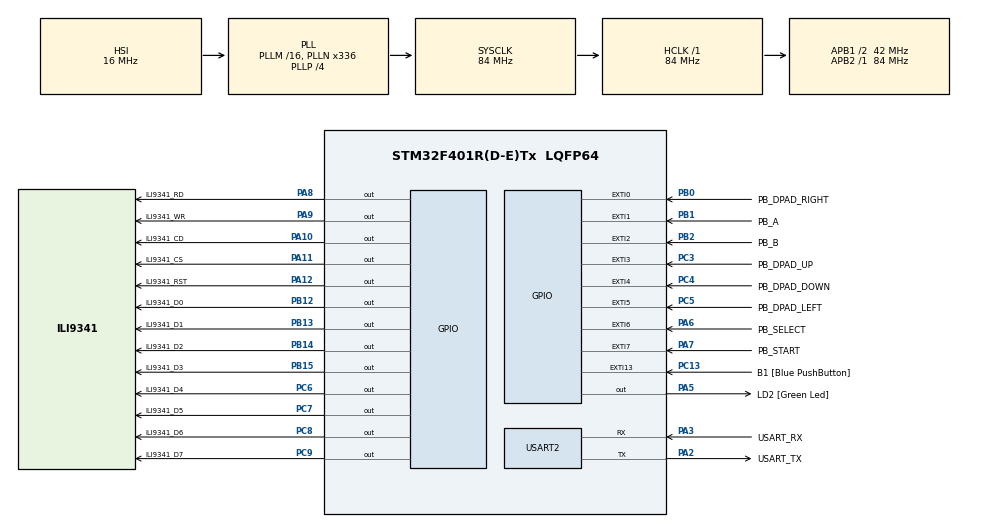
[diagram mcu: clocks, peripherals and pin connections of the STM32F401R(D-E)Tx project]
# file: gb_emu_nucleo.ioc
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Mcu.Family=STM32F4
Mcu.Name=STM32F401R(D-E)Tx
Mcu.Package=LQFP64
NVIC.EXTI0_IRQn=true\:0\:0\:false\:false\:true\:true\:true\:true
NVIC.EXTI1_IRQn=true\:0\:0\:false\:false\:true\:true\:true\:true
NVIC.EXTI2_IRQn=true\:0\:0\:false\:false\:true\:true\:true\:true
NVIC.EXTI3_IRQn=true\:0\:0\:false\:false\:true\:true\:true\:true
NVIC.EXTI4_IRQn=true\:0\:0\:false\:false\:true\:true\:true\:true
NVIC.EXTI9_5_IRQn=true\:0\:0\:false\:false\:true\:true\:true\:true
NVIC.PriorityGroup=NVIC_PRIORITYGROUP_4
PA10.GPIO_Label=ILI9341_CD
PA10.Signal=GPIO_Output
PA11.GPIO_Label=ILI9341_CS
PA11.Signal=GPIO_Output
PA12.GPIO_Label=ILI9341_RST
PA12.Signal=GPIO_Output
PA13.GPIO_Label=TMS
PA13.Mode=Trace_Asynchronous_SW
PA13.Signal=SYS_JTMS-SWDIO
PA14.GPIO_Label=TCK
PA14.Mode=Trace_Asynchronous_SW
PA14.Signal=SYS_JTCK-SWCLK
PA2.GPIO_Label=USART_TX
PA2.GPIO_Mode=GPIO_MODE_AF_PP
PA2.GPIO_PuPd=GPIO_NOPULL
PA2.GPIO_Speed=GPIO_SPEED_FREQ_LOW
PA2.Mode=Asynchronous
PA2.Signal=USART2_TX
PA3.GPIO_Label=USART_RX
PA3.GPIO_Mode=GPIO_MODE_AF_PP
PA3.GPIO_PuPd=GPIO_NOPULL
PA3.GPIO_Speed=GPIO_SPEED_FREQ_LOW
PA3.Mode=Asynchronous
PA3.Signal=USART2_RX
PA5.GPIO_Label=LD2 [Green Led]
PA5.GPIO_Mode=GPIO_MODE_OUTPUT_PP
PA5.GPIO_PuPd=GPIO_NOPULL
PA5.GPIO_Speed=GPIO_SPEED_FREQ_LOW
PA5.Signal=GPIO_Output
PA6.GPIO_Label=PB_SELECT
PA6.GPIO_ModeDefaultEXTI=GPIO_MODE_IT_RISING_FALLING
PA6.Signal=GPXTI6
PA7.GPIO_Label=PB_START
PA7.GPIO_ModeDefaultEXTI=GPIO_MODE_IT_RISING_FALLING
PA7.Signal=GPXTI7
PA8.GPIO_Label=ILI9341_RD
PA8.Signal=GPIO_Output
PA9.GPIO_Label=ILI9341_WR
PA9.Signal=GPIO_Output
PB0.GPIO_Label=PB_DPAD_RIGHT
PB0.GPIO_ModeDefaultEXTI=GPIO_MODE_IT_RISING_FALLING
PB0.Signal=GPXTI0
PB1.GPIO_Label=PB_A
PB1.GPIO_ModeDefaultEXTI=GPIO_MODE_IT_RISING_FALLING
PB1.Signal=GPXTI1
PB12.GPIO_Label=ILI9341_D0
PB12.Signal=GPIO_Output
PB13.GPIO_Label=ILI9341_D1
PB13.Signal=GPIO_Output
PB14.GPIO_Label=ILI9341_D2
PB14.Signal=GPIO_Output
PB15.GPIO_Label=ILI9341_D3
PB15.Signal=GPIO_Output
PB2.GPIO_Label=PB_B
PB2.GPIO_ModeDefaultEXTI=GPIO_MODE_IT_RISING_FALLING
PB2.Signal=GPXTI2
PB3.GPIO_Label=SWO
PB3.Mode=Trace_Asynchronous_SW
PB3.Signal=SYS_JTDO-SWO
PC13-ANTI_TAMP.GPIO_Label=B1 [Blue PushButton]
PC13-ANTI_TAMP.GPIO_ModeDefaultEXTI=GPIO_MODE_IT_FALLING
PC13-ANTI_TAMP.GPIO_PuPd=GPIO_NOPULL
PC13-ANTI_TAMP.Signal=GPXTI13
PC14-OSC32_IN.Mode=LSE-External-Oscillator
PC14-OSC32_IN.Signal=RCC_OSC32_IN
PC15-OSC32_OUT.Mode=LSE-External-Oscillator
PC15-OSC32_OUT.Signal=RCC_OSC32_OUT
PC3.GPIO_Label=PB_DPAD_UP
PC3.GPIO_ModeDefaultEXTI=GPIO_MODE_IT_RISING_FALLING
PC3.Signal=GPXTI3
PC4.GPIO_Label=PB_DPAD_DOWN
PC4.GPIO_ModeDefaultEXTI=GPIO_MODE_IT_RISING_FALLING
PC4.Signal=GPXTI4
PC5.GPIO_Label=PB_DPAD_LEFT
PC5.GPIO_ModeDefaultEXTI=GPIO_MODE_IT_RISING_FALLING
PC5.Signal=GPXTI5
PC6.GPIO_Label=ILI9341_D4
PC6.Signal=GPIO_Output
PC7.GPIO_Label=ILI9341_D5
PC7.Signal=GPIO_Output
PC8.GPIO_Label=ILI9341_D6
PC8.Signal=GPIO_Output
PC9.GPIO_Label=ILI9341_D7
PC9.Signal=GPIO_Output
PH0\ -\ OSC_IN.Mode=HSE-External-Clock-Source
PH0\ -\ OSC_IN.Signal=RCC_OSC_IN
PH1\ -\ OSC_OUT.Mode=HSE-External-Clock-Source
PH1\ -\ OSC_OUT.Signal=RCC_OSC_OUT
ProjectManager.HeapSize=0x200
ProjectManager.StackSize=0x400
ProjectManager.TargetToolchain=STM32CubeIDE
RCC.48MHZClocksFreq_Value=48000000
RCC.AHBFreq_Value=84000000
RCC.APB1CLKDivider=RCC_HCLK_DIV2
RCC.APB1Freq_Value=42000000
RCC.APB1TimFreq_Value=84000000
RCC.APB2Freq_Value=84000000
RCC.APB2TimFreq_Value=84000000
RCC.CortexFreq_Value=84000000
RCC.HCLKFreq_Value=84000000
RCC.HSE_VALUE=8000000
RCC.HSI_VALUE=16000000
RCC.PLLN=336
RCC.PLLP=RCC_PLLP_DIV4
RCC.PLLQ=7
RCC.SYSCLKFreq_VALUE=84000000
RCC.SYSCLKSource=RCC_SYSCLKSOURCE_PLLCLK
RCC.VCOOutputFreq_Value=336000000
TIM10.Channel=TIM_CHANNEL_1
USART2.VirtualMode=VM_ASYNC
VP_TIM10_VS_ClockSourceINT.Mode=Enable_Timer
VP_TIM10_VS_no_output1.Mode=PWM Generation1 No Output
board=NUCLEO-F401RE

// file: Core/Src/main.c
/* USER CODE BEGIN Header */
/**
  ******************************************************************************
  * @file           : main.c
  * @brief          : Main program body
  ******************************************************************************
  * @attention
  *
  * Copyright (c) 2025 STMicroelectronics.
  * All rights reserved.
  *
  * This software is licensed under terms that can be found in the LICENSE file
  * in the root directory of this software component.
  * If no LICENSE file comes with this software, it is provided AS-IS.
  *
  ******************************************************************************
  */
/* USER CODE END Header */
#include "main.h"

/* USER CODE BEGIN Includes */

#include <stdbool.h>

// Include so we can use extern variables
#include "stm32f4xx_it.h"

/* USER CODE END Includes */

TIM_HandleTypeDef htim10;

UART_HandleTypeDef huart2;

/* USER CODE BEGIN PV */

// D-Pad buttons
bool isPressedUp     = false;
bool isPressedDown   = false;
bool isPressedLeft   = false;
bool isPressedRight  = false;

// Start + Select buttons
bool isPressedStart  = false;
bool isPressedSelect = false;

// A + B buttons
bool isPressedA      = false;
bool isPressedB      = false;

/* USER CODE END PV */

void SystemClock_Config(void);
static void MX_GPIO_Init(void);
static void MX_USART2_UART_Init(void);
static void MX_TIM10_Init(void);

int main(void)
{

  /* MCU Configuration--------------------------------------------------------*/

  /* Reset of all peripherals, Initializes the Flash interface and the Systick. */
  HAL_Init();

  /* Configure the system clock */
  SystemClock_Config();

  /* Initialize all configured peripherals */
  MX_GPIO_Init();
  MX_USART2_UART_Init();
  MX_TIM10_Init();

  /* Infinite loop */
  while (1)
  {

  }
}

void SystemClock_Config(void)
{
  RCC_OscInitTypeDef RCC_OscInitStruct = {0};
  RCC_ClkInitTypeDef RCC_ClkInitStruct = {0};

  /** Configure the main internal regulator output voltage
  */
  __HAL_RCC_PWR_CLK_ENABLE();
  __HAL_PWR_VOLTAGESCALING_CONFIG(PWR_REGULATOR_VOLTAGE_SCALE2);

  /** Initializes the RCC Oscillators according to the specified parameters
  * in the RCC_OscInitTypeDef structure.
  */
  RCC_OscInitStruct.OscillatorType = RCC_OSCILLATORTYPE_HSI;
  RCC_OscInitStruct.HSIState = RCC_HSI_ON;
  RCC_OscInitStruct.HSICalibrationValue = RCC_HSICALIBRATION_DEFAULT;
  RCC_OscInitStruct.PLL.PLLState = RCC_PLL_ON;
  RCC_OscInitStruct.PLL.PLLSource = RCC_PLLSOURCE_HSI;
  RCC_OscInitStruct.PLL.PLLM = 16;
  RCC_OscInitStruct.PLL.PLLN = 336;
  RCC_OscInitStruct.PLL.PLLP = RCC_PLLP_DIV4;
  RCC_OscInitStruct.PLL.PLLQ = 7;
  if (HAL_RCC_OscConfig(&RCC_OscInitStruct) != HAL_OK)
  {
    Error_Handler();
  }

  /** Initializes the CPU, AHB and APB buses clocks
  */
  RCC_ClkInitStruct.ClockType = RCC_CLOCKTYPE_HCLK|RCC_CLOCKTYPE_SYSCLK
                              |RCC_CLOCKTYPE_PCLK1|RCC_CLOCKTYPE_PCLK2;
  RCC_ClkInitStruct.SYSCLKSource = RCC_SYSCLKSOURCE_PLLCLK;
  RCC_ClkInitStruct.AHBCLKDivider = RCC_SYSCLK_DIV1;
  RCC_ClkInitStruct.APB1CLKDivider = RCC_HCLK_DIV2;
  RCC_ClkInitStruct.APB2CLKDivider = RCC_HCLK_DIV1;

  if (HAL_RCC_ClockConfig(&RCC_ClkInitStruct, FLASH_LATENCY_2) != HAL_OK)
  {
    Error_Handler();
  }
}

static void MX_TIM10_Init(void)
{

  TIM_OC_InitTypeDef sConfigOC = {0};

  htim10.Instance = TIM10;
  htim10.Init.Prescaler = 0;
  htim10.Init.CounterMode = TIM_COUNTERMODE_UP;
  htim10.Init.Period = 65535;
  htim10.Init.ClockDivision = TIM_CLOCKDIVISION_DIV1;
  htim10.Init.AutoReloadPreload = TIM_AUTORELOAD_PRELOAD_DISABLE;
  if (HAL_TIM_Base_Init(&htim10) != HAL_OK)
  {
    Error_Handler();
  }
  if (HAL_TIM_PWM_Init(&htim10) != HAL_OK)
  {
    Error_Handler();
  }
  sConfigOC.OCMode = TIM_OCMODE_PWM1;
  sConfigOC.Pulse = 0;
  sConfigOC.OCPolarity = TIM_OCPOLARITY_HIGH;
  sConfigOC.OCFastMode = TIM_OCFAST_DISABLE;
  if (HAL_TIM_PWM_ConfigChannel(&htim10, &sConfigOC, TIM_CHANNEL_1) != HAL_OK)
  {
    Error_Handler();
  }

}

static void MX_USART2_UART_Init(void)
{

  huart2.Instance = USART2;
  huart2.Init.BaudRate = 115200;
  huart2.Init.WordLength = UART_WORDLENGTH_8B;
  huart2.Init.StopBits = UART_STOPBITS_1;
  huart2.Init.Parity = UART_PARITY_NONE;
  huart2.Init.Mode = UART_MODE_TX_RX;
  huart2.Init.HwFlowCtl = UART_HWCONTROL_NONE;
  huart2.Init.OverSampling = UART_OVERSAMPLING_16;
  if (HAL_UART_Init(&huart2) != HAL_OK)
  {
    Error_Handler();
  }

}

static void MX_GPIO_Init(void)
{
  GPIO_InitTypeDef GPIO_InitStruct = {0};

  /* GPIO Ports Clock Enable */
  __HAL_RCC_GPIOC_CLK_ENABLE();
  __HAL_RCC_GPIOH_CLK_ENABLE();
  __HAL_RCC_GPIOA_CLK_ENABLE();
  __HAL_RCC_GPIOB_CLK_ENABLE();

  /*Configure GPIO pin Output Level */
  HAL_GPIO_WritePin(GPIOA, LD2_Pin|ILI9341_RD_Pin|ILI9341_WR_Pin|ILI9341_CD_Pin
                          |ILI9341_CS_Pin|ILI9341_RST_Pin, GPIO_PIN_RESET);

  /*Configure GPIO pin Output Level */
  HAL_GPIO_WritePin(GPIOB, ILI9341_D0_Pin|ILI9341_D1_Pin|ILI9341_D2_Pin|ILI9341_D3_Pin, GPIO_PIN_RESET);

  /*Configure GPIO pin Output Level */
  HAL_GPIO_WritePin(GPIOC, ILI9341_D4_Pin|ILI9341_D5_Pin|ILI9341_D6_Pin|ILI9341_D7_Pin, GPIO_PIN_RESET);

  /*Configure GPIO pin : B1_Pin */
  GPIO_InitStruct.Pin = B1_Pin;
  GPIO_InitStruct.Mode = GPIO_MODE_IT_FALLING;
  GPIO_InitStruct.Pull = GPIO_NOPULL;
  HAL_GPIO_Init(B1_GPIO_Port, &GPIO_InitStruct);

  /*Configure GPIO pins : PB_DPAD_UP_Pin PB_DPAD_DOWN_Pin PB_DPAD_LEFT_Pin */
  GPIO_InitStruct.Pin = PB_DPAD_UP_Pin|PB_DPAD_DOWN_Pin|PB_DPAD_LEFT_Pin;
  GPIO_InitStruct.Mode = GPIO_MODE_IT_RISING_FALLING;
  GPIO_InitStruct.Pull = GPIO_NOPULL;
  HAL_GPIO_Init(GPIOC, &GPIO_InitStruct);

  /*Configure GPIO pins : LD2_Pin ILI9341_RD_Pin ILI9341_WR_Pin ILI9341_CD_Pin
                           ILI9341_CS_Pin ILI9341_RST_Pin */
  GPIO_InitStruct.Pin = LD2_Pin|ILI9341_RD_Pin|ILI9341_WR_Pin|ILI9341_CD_Pin
                          |ILI9341_CS_Pin|ILI9341_RST_Pin;
  GPIO_InitStruct.Mode = GPIO_MODE_OUTPUT_PP;
  GPIO_InitStruct.Pull = GPIO_NOPULL;
  GPIO_InitStruct.Speed = GPIO_SPEED_FREQ_LOW;
  HAL_GPIO_Init(GPIOA, &GPIO_InitStruct);

  /*Configure GPIO pins : PB_SELECT_Pin PB_START_Pin */
  GPIO_InitStruct.Pin = PB_SELECT_Pin|PB_START_Pin;
  GPIO_InitStruct.Mode = GPIO_MODE_IT_RISING_FALLING;
  GPIO_InitStruct.Pull = GPIO_NOPULL;
  HAL_GPIO_Init(GPIOA, &GPIO_InitStruct);

  /*Configure GPIO pins : PB_DPAD_RIGHT_Pin PB_A_Pin PB_B_Pin */
  GPIO_InitStruct.Pin = PB_DPAD_RIGHT_Pin|PB_A_Pin|PB_B_Pin;
  GPIO_InitStruct.Mode = GPIO_MODE_IT_RISING_FALLING;
  GPIO_InitStruct.Pull = GPIO_NOPULL;
  HAL_GPIO_Init(GPIOB, &GPIO_InitStruct);

  /*Configure GPIO pins : ILI9341_D0_Pin ILI9341_D1_Pin ILI9341_D2_Pin ILI9341_D3_Pin */
  GPIO_InitStruct.Pin = ILI9341_D0_Pin|ILI9341_D1_Pin|ILI9341_D2_Pin|ILI9341_D3_Pin;
  GPIO_InitStruct.Mode = GPIO_MODE_OUTPUT_PP;
  GPIO_InitStruct.Pull = GPIO_NOPULL;
  GPIO_InitStruct.Speed = GPIO_SPEED_FREQ_LOW;
  HAL_GPIO_Init(GPIOB, &GPIO_InitStruct);

  /*Configure GPIO pins : ILI9341_D4_Pin ILI9341_D5_Pin ILI9341_D6_Pin ILI9341_D7_Pin */
  GPIO_InitStruct.Pin = ILI9341_D4_Pin|ILI9341_D5_Pin|ILI9341_D6_Pin|ILI9341_D7_Pin;
  GPIO_InitStruct.Mode = GPIO_MODE_OUTPUT_PP;
  GPIO_InitStruct.Pull = GPIO_NOPULL;
  GPIO_InitStruct.Speed = GPIO_SPEED_FREQ_LOW;
  HAL_GPIO_Init(GPIOC, &GPIO_InitStruct);

  /* EXTI interrupt init*/
  HAL_NVIC_SetPriority(EXTI0_IRQn, 0, 0);
  HAL_NVIC_EnableIRQ(EXTI0_IRQn);

  HAL_NVIC_SetPriority(EXTI1_IRQn, 0, 0);
  HAL_NVIC_EnableIRQ(EXTI1_IRQn);

  HAL_NVIC_SetPriority(EXTI2_IRQn, 0, 0);
  HAL_NVIC_EnableIRQ(EXTI2_IRQn);

  HAL_NVIC_SetPriority(EXTI3_IRQn, 0, 0);
  HAL_NVIC_EnableIRQ(EXTI3_IRQn);

  HAL_NVIC_SetPriority(EXTI4_IRQn, 0, 0);
  HAL_NVIC_EnableIRQ(EXTI4_IRQn);

  HAL_NVIC_SetPriority(EXTI9_5_IRQn, 0, 0);
  HAL_NVIC_EnableIRQ(EXTI9_5_IRQn);

}

void Error_Handler(void)
{
  __disable_irq();
  while (1)
  {
  }
}
